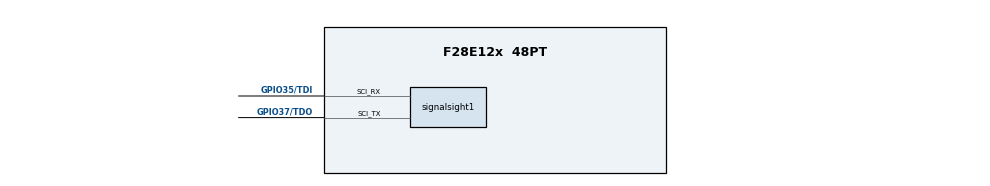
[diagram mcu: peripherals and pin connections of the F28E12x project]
/**
 * @cliArgs --device "F28E12x" --package "48PT" --part "F28E12x_48PT" --context "system" --product "C2000WARE@5.04.00.00"
 * @versions {"tool":"1.21.0+dev"}
 */
/**
 * Import the modules used in this configuration.
 */
const cputimer     = scripting.addModule("/driverlib/cputimer.js", {}, false);
const cputimer1    = cputimer.addInstance();
const signalsight  = scripting.addModule("/utilities/transfer/signalsight.js", {}, false);
const signalsight1 = signalsight.addInstance();
const device_support = scripting.addModule("/driverlib/device_support.js");
const CMD            = scripting.addModule("/utilities/cmd_tool/cmd_syscfg/source/CMD");
const CMD1           = CMD.addInstance();

/**
 * Write custom configuration values to the imported modules.
 */
cputimer1.$name                     = "myCPUTIMER0";
cputimer1.enableInterrupt           = true;
cputimer1.registerInterrupts        = true;
cputimer1.timerPeriod               = 159999;
cputimer1.timerInt.interruptHandler = "cpuTimer1ISR";
cputimer1.timerInt.enableInterrupt  = true;


const divider2       = system.clockTree["PLL_PDIV"];
divider2.divideValue = 2;

const multiplier1         = system.clockTree["PLL_QDIV"];
multiplier1.multiplyValue = 32;

const mux1       = system.clockTree["OSCCLKSRCSEL"];
mux1.inputSelect = "X1_XTAL";

signalsight1.$name                                         = "myMCUSignalSight0";
signalsight1.bufferSize                                    = 200;
signalsight1.exporter.comsLinkModule.loopback              = scripting.forceWrite(false);
signalsight1.exporter.comsLinkModule.wordLenght            = scripting.forceWrite("8");
signalsight1.exporter.comsLinkModule.stop                  = scripting.forceWrite("ONE");
signalsight1.exporter.comsLinkModule.parity                = scripting.forceWrite("SCI_CONFIG_PAR_NONE");
signalsight1.exporter.comsLinkModule.useFifo               = scripting.forceWrite(true);
signalsight1.exporter.comsLinkModule.txFifo                = scripting.forceWrite("SCI_FIFO_TX0");
signalsight1.exporter.comsLinkModule.useCase               = scripting.forceWrite("ALL");
signalsight1.exporter.comsLinkModule.baudRates             = 115200;

signalsight1.exporter.comsLinkModule.sci.$assign           = "SCIA";
signalsight1.exporter.comsLinkModule.sci.sci_rxPin.$assign = "GPIO35/TDI";
signalsight1.exporter.comsLinkModule.sci.sci_txPin.$assign = "GPIO37/TDO";
signalsight1.exporter.comsLinkModule.rxQual.$name          = "myGPIOQUAL0";
signalsight1.exporter.comsLinkModule.txQual.$name          = "myGPIOQUAL1";
signalsight1.hash.$name                                    = "myHashTable0";
signalsight1.hash.hashElements.create(6);
signalsight1.hash.hashElements[0].$name                    = "sineWave1";
signalsight1.hash.hashElements[1].$name                    = "squareWave1";
signalsight1.hash.hashElements[2].$name                    = "triangleWave1";
signalsight1.hash.hashElements[3].$name                    = "sineWave2";
signalsight1.hash.hashElements[4].$name                    = "squareWave2";
signalsight1.hash.hashElements[5].$name                    = "triangleWave2";

/**
 * Pinmux solution for unlocked pins/peripherals. This ensures that minor changes to the automatic solver in a future
 * version of the tool will not impact the pinmux you originally saw.  These lines can be completely deleted in order to
 * re-solve from scratch.
 */
signalsight1.exporter.comsLinkModule.sci.sci_rxPin.$suggestSolution = "A16/C16, GPIO28";

/**
 * Write custom configuration values to the imported modules.
 */
CMD1.$name                    = "generic_flash_lnk";

CMD1.sectionAlignEnable_ramfunc    = true;
CMD1.sectionAlignEnable_text       = true;
CMD1.sectionAlignEnable_binit      = true;
CMD1.sectionAlignEnable_cinit      = true;
CMD1.sectionAlignEnable_switch     = true;
CMD1.sectionAlignEnable_init_array = true;
CMD1.sectionAlignEnable_const      = true;
CMD1.sectionAlignEnable_ovly       = true;
CMD1.sectionMemory_codestart       = "0x080000";
CMD1.sectionMemory_stack           = ["RAMM0"];
CMD1.sectionMemory_bss             = ["RAMGS0"];
CMD1.sectionMemory_data            = ["RAMGS0", "RAMM0", "RAMM1"];
CMD1.sectionMemory_sysmem          = ["RAMGS0"];
CMD1.sectionMemory_ramfunc         = ["FLASH_BANK0_SEC_0_63"];
CMD1.sectionMemory_text            = ["FLASH_BANK0_SEC_0_63"];
CMD1.sectionMemory_binit           = ["FLASH_BANK0_SEC_0_63"];
CMD1.sectionMemory_cinit           = ["FLASH_BANK0_SEC_0_63"];
CMD1.sectionMemory_switch          = ["FLASH_BANK0_SEC_0_63"];
CMD1.sectionMemory_init_array      = ["FLASH_BANK0_SEC_0_63"];
CMD1.sectionMemory_const           = ["FLASH_BANK0_SEC_0_63"];
CMD1.sectionMemory_ovly            = ["FLASH_BANK0_SEC_0_63"];
CMD1.sectionRunFromDifferentAddr_ramfunc = true;
CMD1.sectionRun_ramfunc                  = ["RAMGS0"];
CMD1.sectionBinit_ramfunc                = false;
